# ESP32-H21 register map
Vendor: ESPRESSIF SYSTEMS (SHANGHAI) CO., LTD.; Series: ESP32 H-Series; File version: 1
CPU: RV32IMAC r0p0, little endian, no MPU, no FPU, 0 interrupt priority bits
Address unit: 32 bits
Registers are 32-bit, read-write, reset 0x0 unless marked. A register's access mark holds for its fields unless they carry their own. Offsets are from the block's base; [hi:lo] are bit positions; {n}, {i} and the like mark numbered series; 'fields as' and 'values as' point back to an identical list.

## LP_ANA — LP_ANA Peripheral
Base 0x600B2C00
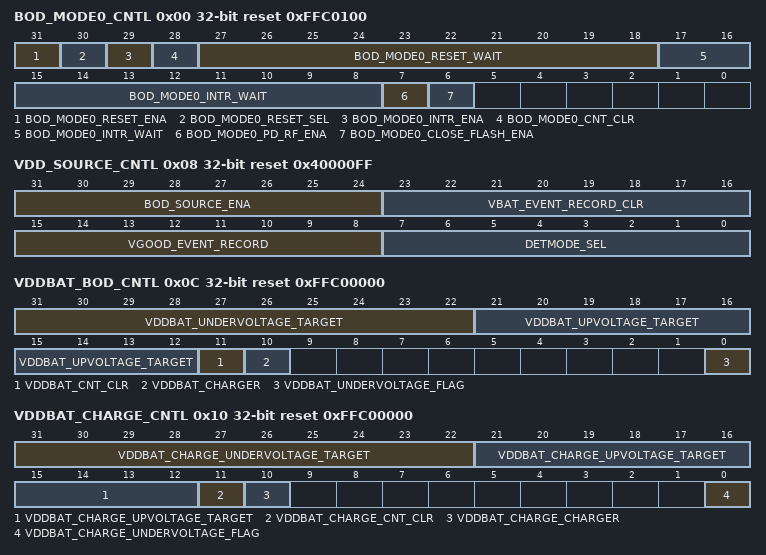
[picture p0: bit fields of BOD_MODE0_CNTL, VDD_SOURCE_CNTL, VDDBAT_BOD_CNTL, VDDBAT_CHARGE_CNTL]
0x00 BOD_MODE0_CNTL reset 0xFFC0100 — need_des
  [31] BOD_MODE0_RESET_ENA — need_des
  [30] BOD_MODE0_RESET_SEL — need_des
  [29] BOD_MODE0_INTR_ENA — need_des
  [28] BOD_MODE0_CNT_CLR — need_des
  [27:18] BOD_MODE0_RESET_WAIT — need_des
  [17:8] BOD_MODE0_INTR_WAIT — need_des
  [7] BOD_MODE0_PD_RF_ENA — need_des
  [6] BOD_MODE0_CLOSE_FLASH_ENA — need_des
0x04 BOD_MODE1_CNTL — need_des
  [31] BOD_MODE1_RESET_ENA
0x08 VDD_SOURCE_CNTL access per field reset 0x40000FF — need_des
  [31:24] BOD_SOURCE_ENA rw — need_des
  [23:16] VBAT_EVENT_RECORD_CLR wo — need_des
  [15:8] VGOOD_EVENT_RECORD ro — need_des
  [7:0] DETMODE_SEL rw — need_des
0x0C VDDBAT_BOD_CNTL access per field reset 0xFFC00000 — need_des
  [31:22] VDDBAT_UNDERVOLTAGE_TARGET rw — need_des
  [21:12] VDDBAT_UPVOLTAGE_TARGET rw — need_des
  [11] VDDBAT_CNT_CLR rw — need_des
  [10] VDDBAT_CHARGER rw — need_des
  [0] VDDBAT_UNDERVOLTAGE_FLAG ro — need_des
0x10 VDDBAT_CHARGE_CNTL access per field reset 0xFFC00000 — need_des
  [31:22] VDDBAT_CHARGE_UNDERVOLTAGE_TARGET rw — need_des
  [21:12] VDDBAT_CHARGE_UPVOLTAGE_TARGET rw — need_des
  [11] VDDBAT_CHARGE_CNT_CLR rw — need_des
  [10] VDDBAT_CHARGE_CHARGER rw — need_des
  [0] VDDBAT_CHARGE_UNDERVOLTAGE_FLAG ro — need_des
0x14 CK_GLITCH_CNTL — need_des
  [31] CK_GLITCH_RESET_ENA
0x18 PG_GLITCH_CNTL — need_des
  [31:26] POWER_GLITCH_RESET_ENA
0x1C FIB_ENABLE reset 0xFF000000 — need_des
  [31:24] ANA_FIB_ENA
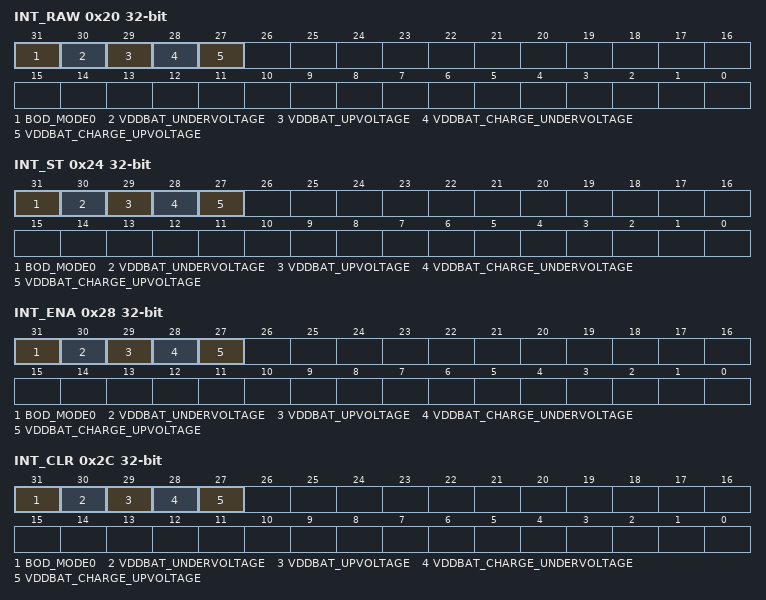
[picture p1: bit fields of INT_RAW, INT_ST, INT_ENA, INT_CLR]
0x20 INT_RAW — need_des
  [31] BOD_MODE0 — need_des
  [30] VDDBAT_UNDERVOLTAGE — need_des
  [29] VDDBAT_UPVOLTAGE — need_des
  [28] VDDBAT_CHARGE_UNDERVOLTAGE — need_des
  [27] VDDBAT_CHARGE_UPVOLTAGE — need_des
0x24 INT_ST ro — need_des
  fields as INT_RAW
0x28 INT_ENA — need_des
  fields as INT_RAW
0x2C INT_CLR wo — need_des
  [31] BOD_MODE0 write-1-clears — need_des
  [30] VDDBAT_UNDERVOLTAGE write-1-clears — need_des
  [29] VDDBAT_UPVOLTAGE write-1-clears — need_des
  [28] VDDBAT_CHARGE_UNDERVOLTAGE write-1-clears — need_des
  [27] VDDBAT_CHARGE_UPVOLTAGE write-1-clears — need_des
0x30 LP_INT_RAW — need_des
  [31] BOD_MODE0
0x34 LP_INT_ST ro — need_des
  [31] BOD_MODE0
0x38 LP_INT_ENA — need_des
  [31] BOD_MODE0
0x3C LP_INT_CLR wo — need_des
  [31] BOD_MODE0 write-1-clears
0x3FC DATE — need_des

## LP_AON — LP_AON Peripheral
Base 0x600B1000
{0x0+4i} STORE{i} (i=0..9) — need_des
  [31:0] DATA
0x28 GPIO_MUX — need_des
  [7:0] SEL
0x2C GPIO_HOLD0 — need_des
0x30 GPIO_HOLD1 — need_des
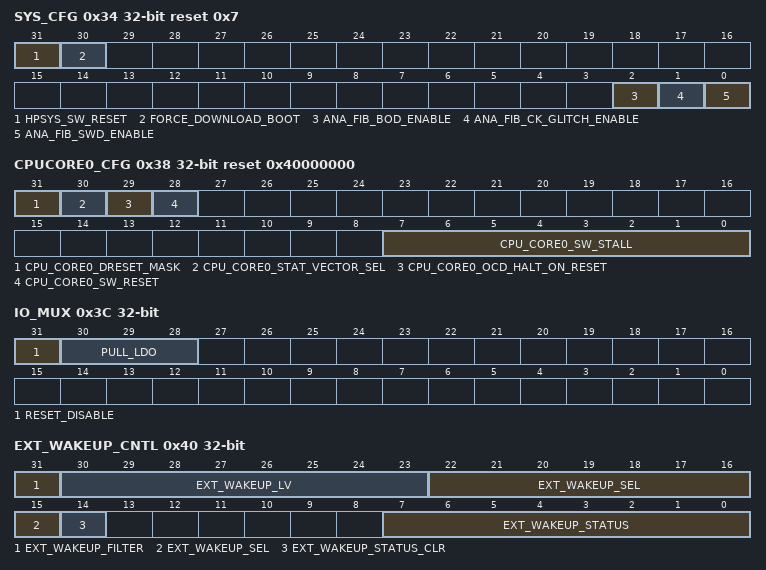
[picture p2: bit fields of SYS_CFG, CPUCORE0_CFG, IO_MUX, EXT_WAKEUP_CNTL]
0x34 SYS_CFG access per field reset 0x7 — need_des
  [31] HPSYS_SW_RESET wo — need_des
  [30] FORCE_DOWNLOAD_BOOT rw — need_des
  [2] ANA_FIB_BOD_ENABLE ro — need_des
  [1] ANA_FIB_CK_GLITCH_ENABLE ro — need_des
  [0] ANA_FIB_SWD_ENABLE ro — need_des
0x38 CPUCORE0_CFG access per field reset 0x40000000 — need_des
  [31] CPU_CORE0_DRESET_MASK rw — need_des
  [30] CPU_CORE0_STAT_VECTOR_SEL rw — need_des
  [29] CPU_CORE0_OCD_HALT_ON_RESET rw — need_des
  [28] CPU_CORE0_SW_RESET wo — need_des
  [7:0] CPU_CORE0_SW_STALL rw — need_des
0x3C IO_MUX — need_des
  [31] RESET_DISABLE — need_des
  [30:28] PULL_LDO — need_des
0x40 EXT_WAKEUP_CNTL access per field — need_des
  [31] EXT_WAKEUP_FILTER rw — need_des
  [30:23] EXT_WAKEUP_LV rw — need_des
  [22:15] EXT_WAKEUP_SEL rw — need_des
  [14] EXT_WAKEUP_STATUS_CLR wo — need_des
  [7:0] EXT_WAKEUP_STATUS ro — need_des
0x44 USB — need_des
  [31] RESET_DISABLE
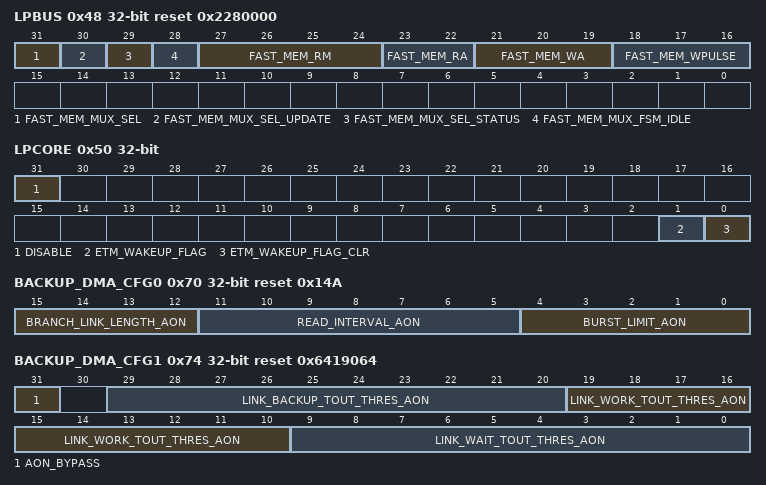
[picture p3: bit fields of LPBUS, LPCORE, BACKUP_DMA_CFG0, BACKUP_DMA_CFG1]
0x48 LPBUS access per field reset 0x2280000 — need_des
  [31] FAST_MEM_MUX_SEL ro — reserved
  [30] FAST_MEM_MUX_SEL_UPDATE ro — reserved
  [29] FAST_MEM_MUX_SEL_STATUS ro — reserved
  [28] FAST_MEM_MUX_FSM_IDLE ro — reserved
  [27:24] FAST_MEM_RM rw — This field controls fast memory RM parameter. 0b0011 for 1.1V operating Voltage, 0b0010 for 1.0V, 0b0000 for 0.9V.
  [23:22] FAST_MEM_RA rw — This field controls fast memory RA parameter. 0b00 for 1.1V/1.0V operating Voltage, 0b01 for 0.9V.
  [21:19] FAST_MEM_WA rw — This field controls fast memory WA parameter. 0b100 for 1.1V operating Voltage, 0b101 for 1.0V, 0b110 for 0.9V.
  [18:16] FAST_MEM_WPULSE rw — This field controls fast memory WPULSE parameter. 0b000 for 1.1V/1.0V/0.9V operating Voltage.
0x4C SDIO_ACTIVE reset 0x2800000 — need_des
  [31:22] SDIO_ACT_DNUM
0x50 LPCORE access per field — need_des
  [31] DISABLE rw — need_des
  [1] ETM_WAKEUP_FLAG rw — need_des
  [0] ETM_WAKEUP_FLAG_CLR wo — need_des
0x54 SAR_CCT — need_des
  [31:29] SAR2_PWDET_CCT
0x58 JTAG_SEL reset 0x80000000 — need_des
  [31] SOFT — If strapping_sel_jtag feature is disabled by efuse, and if neither pad_jtag or usb_jtag is disabled by efuse, this field determines which one jtag between usb_jtag and pad_jtag will be used. 1'b1(default): usb_jtag, 1'b0: pad_jtag.
0x70 BACKUP_DMA_CFG0 reset 0x14A — configure regdma always on register
  [15:12] BRANCH_LINK_LENGTH_AON — Set this field to configure link address.
  [11:5] READ_INTERVAL_AON — Set this field to configure read registers' interval time in reading mode.
  [4:0] BURST_LIMIT_AON — Set this field to configure max value of burst in signle transfer.
0x74 BACKUP_DMA_CFG1 reset 0x6419064 — configure regdma always on register
  [31] AON_BYPASS — reserved
  [29:20] LINK_BACKUP_TOUT_THRES_AON — Set this field to configure maximum waiting time in backup mode.
  [19:10] LINK_WORK_TOUT_THRES_AON — Set this field to configure maximum waiting time in waiting mode.
  [9:0] LINK_WAIT_TOUT_THRES_AON — Set this field to configure the number of consecutive links of link list.
0x78 BACKUP_DMA_CFG2 — configure regdma always on register
  [31:0] LINK_ADDR_AON — Set this field to configure link address.
0x3FC DATE — need_des
